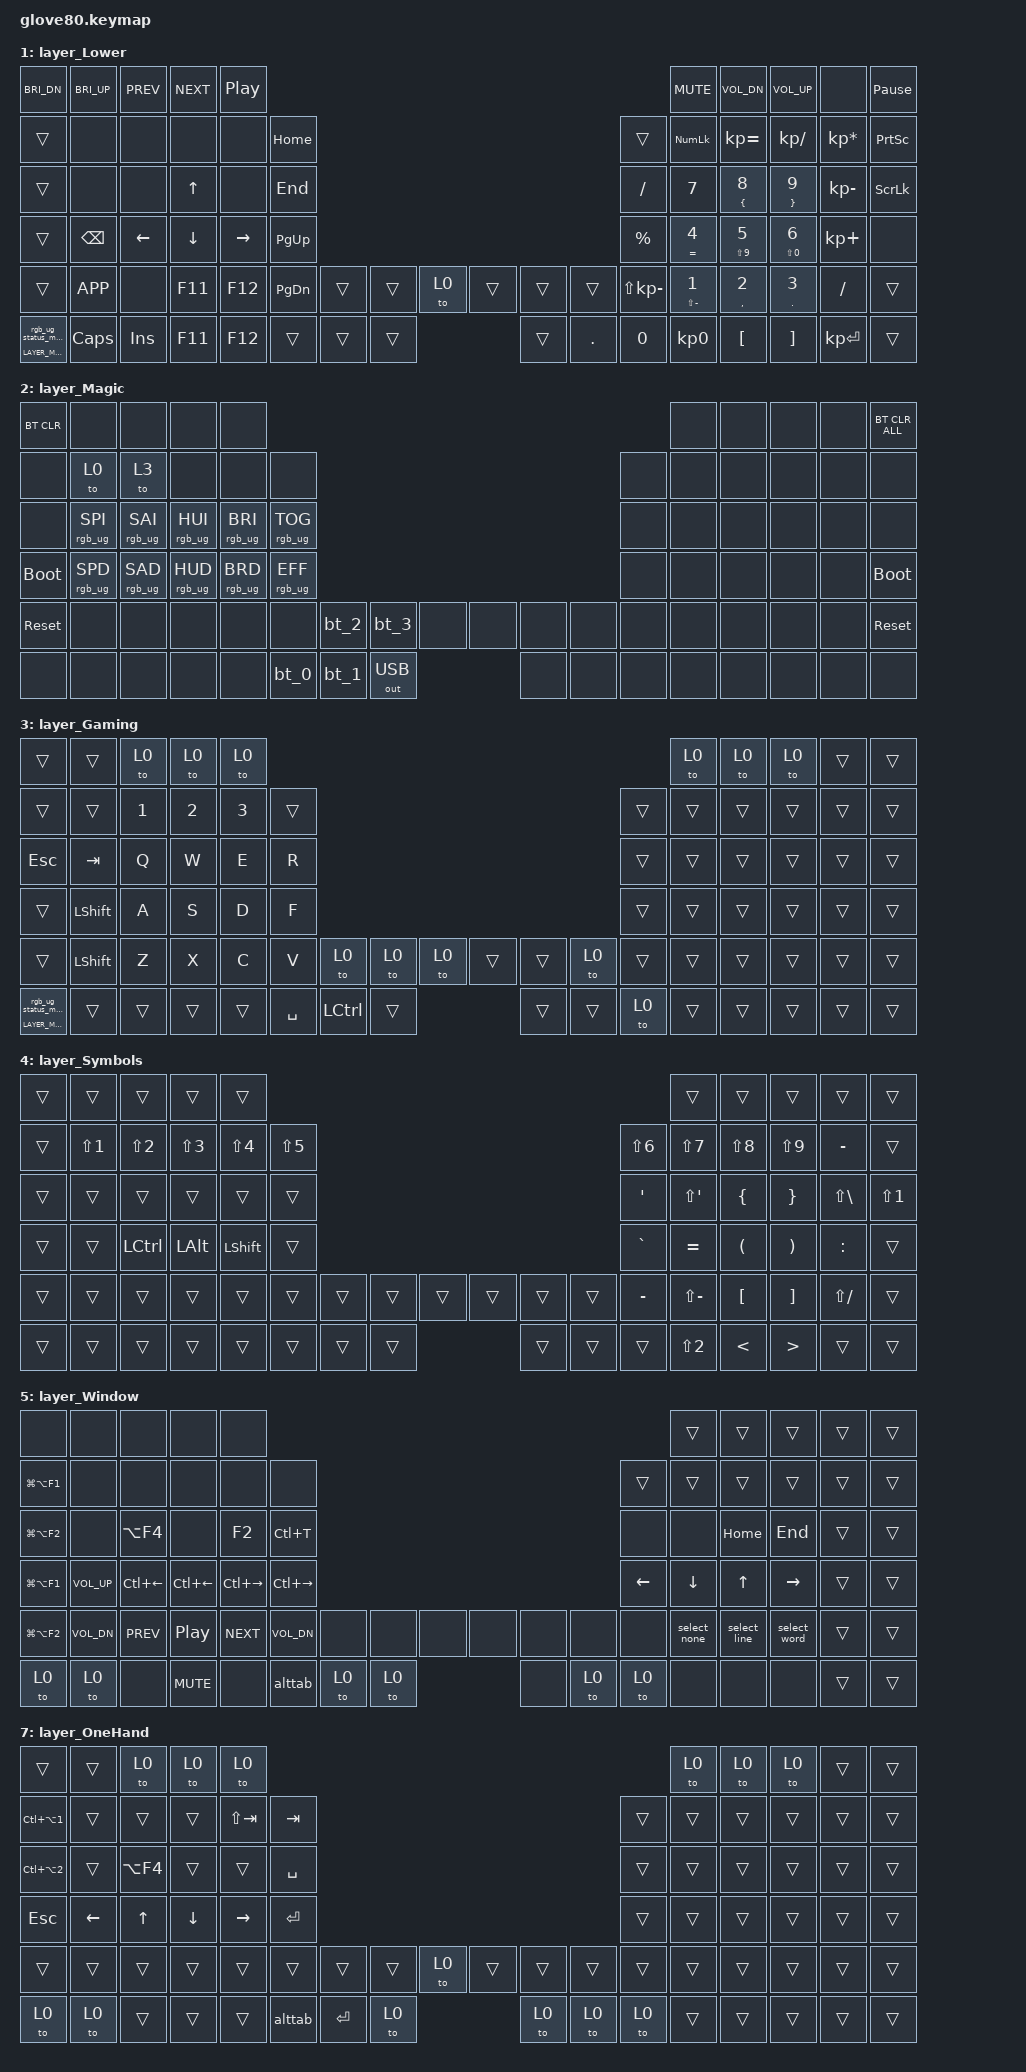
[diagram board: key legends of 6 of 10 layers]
/*
 * Copyright (c) 2020 The ZMK Contributors
 * Copyright (c) 2025 Innaworks Development Limited, trading as MoErgo
 *
 * SPDX-License-Identifier: MIT
 */


/* THIS FILE WAS GENERATED BY GLOVE80 LAYOUT EDITOR
 *
 * This file was generated automatically. You may or may not want to
 * edit it directly.
 */

#include <behaviors.dtsi>
/* Include all behavior includes needed */
#include <dt-bindings/zmk/outputs.h>
#include <dt-bindings/zmk/keys.h>
#include <dt-bindings/zmk/bt.h>
#include <dt-bindings/zmk/rgb.h>

/* On demand includes */


/* Helper Macros, based on https://github.com/urob/zmk-helpers/ */

#pragma once

#define ZMK_HELPER_STRINGIFY(x) #x

// Preprocessor mechanism to overload macros, cf. https://stackoverflow.com/a/27051616/6114651
#define VARGS_(_10, _9, _8, _7, _6, _5, _4, _3, _2, _1, N, ...) N
#define VARGS(...) VARGS_(__VA_ARGS__, 10, 9, 8, 7, 6, 5, 4, 3, 2, 1, 0)
#define CONCAT_(a, b) a##b
#define CONCAT(a, b) CONCAT_(a, b)

#define ZMK_BEHAVIOR_CORE_tap_dance  \
    compatible = "zmk,behavior-tap-dance"; \
    #binding-cells = <0>

#define ZMK_BEHAVIOR(name, type, ...) \
    name: name { \
        ZMK_BEHAVIOR_CORE_ ## type; \
        __VA_ARGS__ \
    };

#define ZMK_TAP_DANCE(name, ...) \
    ZMK_BEHAVIOR(name, tap_dance, __VA_ARGS__)

#define ZMK_TD_LAYER(name, layer) \
    ZMK_TAP_DANCE(name, \
        tapping-term-ms = <200>; \
        bindings = <&mo layer>, <&to layer>; \
)

/* Automatically generated layer name #define */
#define LAYER_Base 0
#define LAYER_Lower 1
#define LAYER_Magic 2
#define LAYER_Gaming 3
#define LAYER_Symbols 4
#define LAYER_Window 5
#define LAYER_Nav 6
#define LAYER_OneHand 7
#define LAYER_Base_mac 8
#define LAYER_Nav_mac 9

/* To deal with the situation where there is no Lower layer, to keep &lower happy */
#ifndef LAYER_Lower
#define LAYER_Lower 0
#endif

/* Custom Device-tree */


/* Input Listeners */


/* System behavior and Macros */
/ {
    behaviors {
        ZMK_TD_LAYER(lower, LAYER_Lower)
    };
};

/ {
    macros {
        rgb_ug_status_macro: rgb_ug_status_macro {
            label = "RGB_UG_STATUS";
            compatible = "zmk,behavior-macro";
            #binding-cells = <0>;
            bindings
                = <&rgb_ug RGB_STATUS>;
        };
    };
};


/ {
#ifdef BT_DISC_CMD
    behaviors {
        bt_0: bt_0 {
            compatible = "zmk,behavior-tap-dance";
            label = "BT_0";
            #binding-cells = <0>;
            tapping-term-ms = <200>;
            bindings = <&bt_select_0>, <&bt BT_DISC 0>;
        };
        bt_1: bt_1 {
            compatible = "zmk,behavior-tap-dance";
            label = "BT_1";
            #binding-cells = <0>;
            tapping-term-ms = <200>;
            bindings = <&bt_select_1>, <&bt BT_DISC 1>;
        };
        bt_2: bt_2 {
            compatible = "zmk,behavior-tap-dance";
            label = "BT_2";
            #binding-cells = <0>;
            tapping-term-ms = <200>;
            bindings = <&bt_select_2>, <&bt BT_DISC 2>;
        };
        bt_3: bt_3 {
            compatible = "zmk,behavior-tap-dance";
            label = "BT_3";
            #binding-cells = <0>;
            tapping-term-ms = <200>;
            bindings = <&bt_select_3>, <&bt BT_DISC 3>;
        };
    };
    macros {
        bt_select_0: bt_select_0 {
            label = "BT_SELECT_0";
            compatible = "zmk,behavior-macro";
            #binding-cells = <0>;
            bindings
                = <&out OUT_BLE>,
                  <&bt BT_SEL 0>;
        };
        bt_select_1: bt_select_1 {
            label = "BT_SELECT_1";
            compatible = "zmk,behavior-macro";
            #binding-cells = <0>;
            bindings
                = <&out OUT_BLE>,
                  <&bt BT_SEL 1>;
        };
        bt_select_2: bt_select_2 {
            label = "BT_SELECT_2";
            compatible = "zmk,behavior-macro";
            #binding-cells = <0>;
            bindings
                = <&out OUT_BLE>,
                  <&bt BT_SEL 2>;
        };
        bt_select_3: bt_select_3 {
            label = "BT_SELECT_3";
            compatible = "zmk,behavior-macro";
            #binding-cells = <0>;
            bindings
                = <&out OUT_BLE>,
                  <&bt BT_SEL 3>;
        };
    };
#else
    macros {
        bt_0: bt_0 {
            label = "BT_0";
            compatible = "zmk,behavior-macro";
            #binding-cells = <0>;
            bindings
                = <&out OUT_BLE>,
                  <&bt BT_SEL 0>;
        };
        bt_1: bt_1 {
            label = "BT_1";
            compatible = "zmk,behavior-macro";
            #binding-cells = <0>;
            bindings
                = <&out OUT_BLE>,
                  <&bt BT_SEL 1>;
        };
        bt_2: bt_2 {
            label = "BT_2";
            compatible = "zmk,behavior-macro";
            #binding-cells = <0>;
            bindings
                = <&out OUT_BLE>,
                  <&bt BT_SEL 2>;
        };
        bt_3: bt_3 {
            label = "BT_3";
            compatible = "zmk,behavior-macro";
            #binding-cells = <0>;
            bindings
                = <&out OUT_BLE>,
                  <&bt BT_SEL 3>;
        };
    };
#endif
};

/ {
    behaviors {
        magic: magic {
            compatible = "zmk,behavior-hold-tap";
            label = "MAGIC_HOLD_TAP";
            #binding-cells = <2>;
            flavor = "tap-preferred";
            tapping-term-ms = <200>;
            bindings = <&mo>, <&rgb_ug_status_macro>;
        };
    };
};

/* #define for key positions */
#define POS_LH_T1 52
#define POS_LH_T2 53
#define POS_LH_T3 54
#define POS_LH_T4 69
#define POS_LH_T5 70
#define POS_LH_T6 71
#define POS_LH_C1R2 15
#define POS_LH_C1R3 27
#define POS_LH_C1R4 39
#define POS_LH_C1R5 51
#define POS_LH_C2R1 4
#define POS_LH_C2R2 14
#define POS_LH_C2R3 26
#define POS_LH_C2R4 38
#define POS_LH_C2R5 50
#define POS_LH_C2R6 68
#define POS_LH_C3R1 3
#define POS_LH_C3R2 13
#define POS_LH_C3R3 25
#define POS_LH_C3R4 37
#define POS_LH_C3R5 49
#define POS_LH_C3R6 67
#define POS_LH_C4R1 2
#define POS_LH_C4R2 12
#define POS_LH_C4R3 24
#define POS_LH_C4R4 36
#define POS_LH_C4R5 48
#define POS_LH_C4R6 66
#define POS_LH_C5R1 1
#define POS_LH_C5R2 11
#define POS_LH_C5R3 23
#define POS_LH_C5R4 35
#define POS_LH_C5R5 47
#define POS_LH_C5R6 65
#define POS_LH_C6R1 0
#define POS_LH_C6R2 10
#define POS_LH_C6R3 22
#define POS_LH_C6R4 34
#define POS_LH_C6R5 46
#define POS_LH_C6R6 64
#define POS_RH_T1 57
#define POS_RH_T2 56
#define POS_RH_T3 55
#define POS_RH_T4 74
#define POS_RH_T5 73
#define POS_RH_T6 72
#define POS_RH_C1R2 16
#define POS_RH_C1R3 28
#define POS_RH_C1R4 40
#define POS_RH_C1R5 58
#define POS_RH_C2R1 5
#define POS_RH_C2R2 17
#define POS_RH_C2R3 29
#define POS_RH_C2R4 41
#define POS_RH_C2R5 59
#define POS_RH_C2R6 75
#define POS_RH_C3R1 6
#define POS_RH_C3R2 18
#define POS_RH_C3R3 30
#define POS_RH_C3R4 42
#define POS_RH_C3R5 60
#define POS_RH_C3R6 76
#define POS_RH_C4R1 7
#define POS_RH_C4R2 19
#define POS_RH_C4R3 31
#define POS_RH_C4R4 43
#define POS_RH_C4R5 61
#define POS_RH_C4R6 77
#define POS_RH_C5R1 8
#define POS_RH_C5R2 20
#define POS_RH_C5R3 32
#define POS_RH_C5R4 44
#define POS_RH_C5R5 62
#define POS_RH_C5R6 78
#define POS_RH_C6R1 9
#define POS_RH_C6R2 21
#define POS_RH_C6R3 33
#define POS_RH_C6R4 45
#define POS_RH_C6R5 63
#define POS_RH_C6R6 79

/* Custom Defined Behaviors */
/ {
// Based on Sunaku's Keymap v29 
// - https://github.com/sunaku/glove80-keymaps

behaviors {

    //////////////////////////////////////////////////////////////////////////
    //
    // Miryoku layers and home row mods (ported from my QMK endgame)
    // - https://sunaku.github.io/home-row-mods.html#porting-to-zmk
    // - https://github.com/urob/zmk-config#timeless-homerow-mods
    //
    //////////////////////////////////////////////////////////////////////////

    //
    // HOMEY_HOLDING_TYPE defines the flavor of ZMK hold-tap behavior to use
    // for the pinky, ring, and middle fingers (which are assigned to Super,
    // Alt, and Ctrl respectively in the Miryoku system) on home row keys.
    //
    #ifndef HOMEY_HOLDING_TYPE
    #define HOMEY_HOLDING_TYPE "tap-preferred"
    #endif

    //
    // HOMEY_HOLDING_TIME defines how long you need to hold (milliseconds)
    // home row mod keys in order to send their modifiers to the computer
    // (i.e. "register" them) for mod-click mouse usage (e.g. Ctrl-Click).
    //
    #ifndef HOMEY_HOLDING_TIME
    #define HOMEY_HOLDING_TIME 200 // TAPPING_TERM + ALLOW_CROSSOVER_AFTER
    #endif

    //
    // HOMEY_STREAK_DECAY defines how long you need to wait (milliseconds)
    // after typing before you can use home row mods again.  It prevents
    // unintended activation of home row mods when you're actively typing.
    //
    #ifndef HOMEY_STREAK_DECAY
    #define HOMEY_STREAK_DECAY 170 // global-quick-tap-ms
    #endif

    //
    // HOMEY_REPEAT_DECAY defines how much time you have left (milliseconds)
    // after tapping a key to hold it again in order to make it auto-repeat.
    //
    #ifndef HOMEY_REPEAT_DECAY
    #define HOMEY_REPEAT_DECAY 300 // "tap then hold" for key auto-repeat
    #endif

    //
    // SHIFT_HOLDING_TYPE defines the flavor of ZMK hold-tap behavior to use
    // for index fingers (which Miryoku assigns to Shift) on home row keys.
    //
    // NOTE: The "tap-preferred" flavor of ZMK hold-tap for index finger keys
    // allows faster activation of the Shift modifier (without having to wait
    // for the modified key to be released as the "balanced" flavor requires).
    // Typing streaks and the `hold-trigger-on-release` setting are disabled
    // for the index fingers so as not to hinder their speed and dexterity.
    //
    #ifndef SHIFT_HOLDING_TYPE
    #define SHIFT_HOLDING_TYPE "tap-preferred"
    #endif

    //
    // SHIFT_HOLDING_TIME defines how long you need to hold (milliseconds)
    // index finger keys in order to send their modifiers to the computer
    // (i.e. "register" them) for mod-click mouse usage (e.g. Shift-Click).
    //
    // CAUTION: You'll need to perform inward rolls from pinky->ring->middle
    // fingers toward the index fingers when activating multiple modifiers
    // because `hold-trigger-on-release` is disabled for the index fingers.
    // Otherwise, you may be surprised that the index fingers' modifier is
    // sent immediately without the rest of your multi-mod chord when you
    // perform outward rolls from your index fingers toward your pinkies.
    //
    #ifndef SHIFT_HOLDING_TIME
    #define SHIFT_HOLDING_TIME 170
    #endif

    //
    // SHIFT_STREAK_DECAY defines how long you need to wait (milliseconds)
    // after typing before you can use home row mods again.  It prevents
    // unintended activation of home row mods when you're actively typing.
    //
    #ifndef SHIFT_STREAK_DECAY
    #define SHIFT_STREAK_DECAY 50 // global-quick-tap-ms
    #endif

    //
    // SHIFT_REPEAT_DECAY defines how much time you have left (milliseconds)
    // after tapping a key to hold it again in order to make it auto-repeat.
    //
    #ifndef SHIFT_REPEAT_DECAY
    #define SHIFT_REPEAT_DECAY 300 // "tap then hold" for key auto-repeat
    #endif

    //
    // THUMB_HOLDING_TYPE defines the flavor of ZMK hold-tap behavior to use
    // for the thumbs (which are assigned to 6 layers in the Miryoku system).
    //
    // NOTE: The "balanced" flavor of ZMK hold-tap provides instant modifier
    // activation for the symbol layer (if the tapped symbol key is released
    // while the thumb layer key is still held down) for quicker programming.
    //
    #ifndef THUMB_HOLDING_TYPE
    #define THUMB_HOLDING_TYPE "balanced"
    #endif

    //
    // THUMB_HOLDING_TIME defines how long you need to hold (milliseconds)
    // a thumb key to activate a layer.  Shorter holds are treated as taps.
    //
    #ifndef THUMB_HOLDING_TIME
    #define THUMB_HOLDING_TIME 230
    #endif

    //
    // THUMB_REPEAT_DECAY defines how much time you have left (milliseconds)
    // after tapping a key to hold it again in order to make it auto-repeat.
    //
    #ifndef THUMB_REPEAT_DECAY
    #define THUMB_REPEAT_DECAY 300 // "tap then hold" for key auto-repeat
    #endif

    //
    // LSPACE_HOLDING_TIME defines how long you need to hold (milliseconds)
    // the LSPACE thumb key to activate.  Shorter holds are treated as taps.
    //
    #ifndef LSPACE_HOLDING_TIME
    #define LSPACE_HOLDING_TIME 270
    #endif

    //
    // LSPACE_REPEAT_DECAY defines how much time you have left (milliseconds)
    // after tapping a key to hold it again in order to make it auto-repeat.
    //
    #ifndef LSPACE_REPEAT_DECAY
    #define LSPACE_REPEAT_DECAY 200 // "tap then hold" for key auto-repeat
    #endif

    //
    // LSPACE_STREAK_DECAY defines how long you need to wait (milliseconds)
    // after typing before you can use home row mods again.  It prevents
    // unintended activation of home row mods when you're actively typing.
    //
    #ifndef LSPACE_STREAK_DECAY
    #define LSPACE_STREAK_DECAY 80 // global-quick-tap-ms
    #endif

    //
    // RSPACE_HOLDING_TIME defines how long you need to hold (milliseconds)
    // the RSPACE thumb key to activate.  Shorter holds are treated as taps.
    //
    #ifndef RSPACE_HOLDING_TIME
    #define RSPACE_HOLDING_TIME 250
    #endif

    //
    // RSPACE_REPEAT_DECAY defines how much time you have left (milliseconds)
    // after tapping a key to hold it again in order to make it auto-repeat.
    //
    #ifndef RSPACE_REPEAT_DECAY
    #define RSPACE_REPEAT_DECAY 200 // "tap then hold" for key auto-repeat
    #endif

    //
    // RSPACE_STREAK_DECAY defines how long you need to wait (milliseconds)
    // after typing before you can use home row mods again.  It prevents
    // unintended activation of home row mods when you're actively typing.
    //
    #ifndef RSPACE_STREAK_DECAY
    #define RSPACE_STREAK_DECAY 250 // global-quick-tap-ms
    #endif

    //
    // Glove80 key positions index for positional hold-tap
    // - https://discord.com/channels/877392805654306816/937645688244826154/1066713913351221248
    // - https://media.discordapp.net/attachments/937645688244826154/1066713913133121556/image.png
    //
    // |------------------------|------------------------|
    // | LEFT_HAND_KEYS         |        RIGHT_HAND_KEYS |
    // |                        |                        |
    // |  0  1  2  3  4         |          5  6  7  8  9 |
    // | 10 11 12 13 14 15      |      16 17 18 19 20 21 |
    // | 22 23 24 25 26 27      |      28 29 30 31 32 33 |
    // | 34 35 36 37 38 39      |      40 41 42 43 44 45 |
    // | 46 47 48 49 50 51      |      58 59 60 61 62 63 |
    // | 64 65 66 67 68         |         75 76 77 78 79 |
    // |                69 52   |   57 74                |
    // |                 70 53  |  56 73                 |
    // |                  71 54 | 55 72                  |
    // |------------------------|------------------------|
    //
    #define LEFT_HAND_KEYS      \
          0  1  2  3  4         \
         10 11 12 13 14 15      \
         22 23 24 25 26 27      \
         34 35 36 37 38 39      \
         46 47 48 49 50 51      \
         64 65 66 67 68
    #define RIGHT_HAND_KEYS     \
                                           5  6  7  8  9 \
                                       16 17 18 19 20 21 \
                                       28 29 30 31 32 33 \
                                       40 41 42 43 44 45 \
                                       58 59 60 61 62 63 \
                                          75 76 77 78 79
    #define THUMB_KEYS          \
                        69 52       57 74                \
                         70 53     56 73                 \
                          71 54   55 72

    // vtr custom
    thumb_to: thumb_to_layer {
        compatible = "zmk,behavior-hold-tap";
        label = "MIRYOKU_THUMB_LAYER";
        flavor = THUMB_HOLDING_TYPE;
        tapping-term-ms = <THUMB_HOLDING_TIME>;
        quick-tap-ms = <THUMB_REPEAT_DECAY>; // enable repeat
        //global-quick-tap; // no typing streak
        //retro-tap; // don't allow slow (hold-like) taps
        #binding-cells = <2>;
        bindings = <&to>, <&kp>;
    };

    // Home row mod-tap keys for all except index fingers
    //
    homey_left: miryoku_home_row_mods_left_hand {
        compatible = "zmk,behavior-hold-tap";
        label = "HOME_ROW_MODS_LEFT_HAND";
        flavor = HOMEY_HOLDING_TYPE;
        hold-trigger-key-positions = <RIGHT_HAND_KEYS THUMB_KEYS>;
        hold-trigger-on-release; // wait for other home row mods
        tapping-term-ms = <HOMEY_HOLDING_TIME>;
        quick-tap-ms = <HOMEY_REPEAT_DECAY>;
        require-prior-idle-ms = <HOMEY_STREAK_DECAY>;
        #binding-cells = <2>;
        bindings = <&kp>, <&kp>;
    };
    homey_right: miryoku_home_row_mods_right_hand {
        compatible = "zmk,behavior-hold-tap";
        label = "HOME_ROW_MODS_RIGHT_HAND";
        flavor = HOMEY_HOLDING_TYPE;
        hold-trigger-key-positions = <LEFT_HAND_KEYS THUMB_KEYS>;
        hold-trigger-on-release; // wait for other home row mods
        tapping-term-ms = <HOMEY_HOLDING_TIME>;
        quick-tap-ms = <HOMEY_REPEAT_DECAY>;
        require-prior-idle-ms = <HOMEY_STREAK_DECAY>;
        #binding-cells = <2>;
        bindings = <&kp>, <&kp>;
    };

    //
    // Special home row mod-tap keys for the index fingers
    //
    shift_left: miryoku_home_row_mods_left_shift_shift {
        compatible = "zmk,behavior-hold-tap";
        label = "HOME_ROW_MODS_LEFT_SHIFT_SHIFT";
        flavor = SHIFT_HOLDING_TYPE;
        hold-trigger-key-positions = <RIGHT_HAND_KEYS THUMB_KEYS>;
        //hold-trigger-on-release; // don't wait for other mods
        tapping-term-ms = <SHIFT_HOLDING_TIME>;
        quick-tap-ms = <SHIFT_REPEAT_DECAY>;
        require-prior-idle-ms = <SHIFT_STREAK_DECAY>;
        #binding-cells = <2>;
        bindings = <&kp>, <&kp>;
    };
    shift_right: miryoku_home_row_mods_right_shift_shift {
        compatible = "zmk,behavior-hold-tap";
        label = "HOME_ROW_MODS_RIGHT_SHIFT_SHIFT";
        flavor = SHIFT_HOLDING_TYPE;
        hold-trigger-key-positions = <LEFT_HAND_KEYS THUMB_KEYS>;
        //hold-trigger-on-release; // don't wait for other mods
        tapping-term-ms = <SHIFT_HOLDING_TIME>;
        quick-tap-ms = <SHIFT_REPEAT_DECAY>;
        require-prior-idle-ms = <SHIFT_STREAK_DECAY>;
        #binding-cells = <2>;
        bindings = <&kp>, <&kp>;
    };

    //
    // Thumb cluster hold-tap keys for Miryoku layers
    //
    thumb: thumb_layer_access {
        compatible = "zmk,behavior-hold-tap";
        label = "THUMB_LAYER_ACCESS";
        flavor = THUMB_HOLDING_TYPE;
        tapping-term-ms = <THUMB_HOLDING_TIME>;
        quick-tap-ms = <THUMB_REPEAT_DECAY>; // enable repeat
        #binding-cells = <2>;
        bindings = <&mo>, <&kp>;
    };
    lspace: miryoku_thumb_layer_lspacebar {
        compatible = "zmk,behavior-hold-tap";
        label = "MIRYOKU_THUMB_LAYER_LSPACEBAR";
        flavor = THUMB_HOLDING_TYPE;
        tapping-term-ms = <LSPACE_HOLDING_TIME>;
        quick-tap-ms = <LSPACE_REPEAT_DECAY>; // enable repeat
        require-prior-idle-ms = <LSPACE_STREAK_DECAY>;
        retro-tap; // allow slow (hold-like) taps
        #binding-cells = <2>;
        bindings = <&mo>, <&kp>;
    };
    rspace: miryoku_thumb_layer_rspacebar {
        compatible = "zmk,behavior-hold-tap";
        label = "MIRYOKU_THUMB_LAYER_RSPACEBAR";
        flavor = THUMB_HOLDING_TYPE;
        tapping-term-ms = <RSPACE_HOLDING_TIME>;
        quick-tap-ms = <RSPACE_REPEAT_DECAY>; // enable repeat
        require-prior-idle-ms = <RSPACE_STREAK_DECAY>;
        retro-tap; // allow slow (hold-like) taps
        #binding-cells = <2>;
        bindings = <&mo>, <&kp>;
    };

    //////////////////////////////////////////////////////////////////////////
    //
    // Custom shifted pairs
    //
    //////////////////////////////////////////////////////////////////////////

    //
    // Shift + CapsWord = CapsLock
    //
    cappy: capsword_and_capslock {
        compatible = "zmk,behavior-mod-morph";
        label = "CAPSWORD_AND_CAPSLOCK";
        #binding-cells = <0>;
        bindings = <&caps_word>, <&kp CAPSLOCK>;
        mods = <(MOD_LSFT|MOD_RSFT)>;
    };

    //////////////////////////////////////////////////////////////////////////
    //
    // ZMK global overrides
    //
    //////////////////////////////////////////////////////////////////////////

    //
    // CapsWord - ported from Pascal Getreuer's extension for QMK
    // - https://zmk.dev/docs/behaviors/caps-word
    // - https://getreuer.info/posts/keyboards/caps-word/index.html
    //
    behavior_caps_word {
        continue-list = <
            UNDERSCORE MINUS
            BACKSPACE DELETE
            N1 N2 N3 N4 N5 N6 N7 N8 N9 N0
        >;
    };

};

    // |------------------------|------------------------|
    // | LEFT_HAND_KEYS         |        RIGHT_HAND_KEYS |
    // |                        |                        |
    // |  0  1  2  3  4         |          5  6  7  8  9 |
    // | 10 11 12 13 14 15      |      16 17 18 19 20 21 |
    // | 22 23 24 25 26 27      |      28 29 30 31 32 33 |
    // | 34 35 36 37 38 39      |      40 41 42 43 44 45 |
    // | 46 47 48 49 50 51      |      58 59 60 61 62 63 |
    // | 64 65 66 67 68         |         75 76 77 78 79 |
    // |                69 52   |   57 74                |
    // |                 70 53  |  56 73                 |
    // |                  71 54 | 55 72                  |
    // |------------------------|------------------------|
    //
combos {
    compatible = "zmk,combos";
    combo_special_e {
            timeout-ms = <100>;
            key-positions = <45 25>;
            bindings = <&kp RA(E)>;
    };
              //ê
    combo_special_e2 {
            timeout-ms = <150>;
            key-positions = <45 44 25>;
            bindings = <&circun_e>;
    };
              //~a
    combo_special_a2 {
            timeout-ms = <100>;
            key-positions = <45 35>;
            bindings = <&tild_a>;
    };
              //á
    combo_special_a {
            timeout-ms = <100>;
            key-positions = <45 44 35>;
            bindings = <&kp RA(A)>;
    };
              //ó
    combo_special_o {
            timeout-ms = <100>;
            key-positions = <45 31>;
            bindings = <&kp RA(O)>;
    };
              //ç
    combo_special_c {
            timeout-ms = <100>;
            key-positions = <45 49>;
            bindings = <&kp RA(C)>;
    };
};

macros {
    // vtr custom
    // special letters
              // ~a
    ZMK_MACRO(tild_a,
        wait-ms = <10>;
        tap-ms = <40>;
        bindings = <&kp LS(GRAVE) &kp A>;
    )
              // ê
    ZMK_MACRO(circun_e,
        wait-ms = <10>;
        tap-ms = <40>;
        bindings = <&kp LS(NUMBER_6) &kp E>;
    )
    // window movement
    ZMK_MACRO(alttab,
        bindings =  <&macro_press &kp LALT> // leave GUI down to keep menu up
                , <&macro_tap &kp TAB> // combines with shift fine
                , <&macro_tap &sk LALT> // this will release GUI after a timeout
                , <&macro_release &kp LALT> // now release the previous hold
                        ;
        )
    ZMK_MACRO(winleft,
        bindings =  <&macro_press &kp LGUI> // leave GUI down to keep menu up
                , <&macro_tap &kp LEFT> // combines with shift fine
                , <&macro_tap &sk LGUI> // this will release GUI after a timeout
                , <&macro_release &kp LGUI> // now release the previous hold
                        ;
        )
    ZMK_MACRO(winright,
        bindings =  <&macro_press &kp LGUI> // leave GUI down to keep menu up
                , <&macro_tap &kp RIGHT> // combines with shift fine
                , <&macro_tap &sk LGUI> // this will release GUI after a timeout
                , <&macro_release &kp LGUI> // now release the previous hold
                        ;
        )
    ZMK_MACRO(winup,
        bindings =  <&macro_press &kp LGUI> // leave GUI down to keep menu up
                , <&macro_tap &kp UP> // combines with shift fine
                , <&macro_tap &sk LGUI> // this will release GUI after a timeout
                , <&macro_release &kp LGUI> // now release the previous hold
                        ;
        )
    ZMK_MACRO(windown,
        bindings =  <&macro_press &kp LGUI> // leave GUI down to keep menu up
                , <&macro_tap &kp DOWN> // combines with shift fine
                , <&macro_tap &sk LGUI> // this will release GUI after a timeout
                , <&macro_release &kp LGUI> // now release the previous hold
                        ;
        )
    ZMK_MACRO(winbar,
        bindings =  <&macro_press &kp LGUI> // leave GUI down to keep menu up
                , <&macro_tap &kp SPACE> // combines with shift fine
                , <&macro_release &kp LGUI> // now release the previous hold
                        ;
    )
    //////////////////////////////////////////////////////////////////////////
    //
    // Approximation of Pascal Getreuer's Select Word macro from QMK
    // - https://getreuer.info/posts/keyboards/select-word/index.html
    //
    //////////////////////////////////////////////////////////////////////////
    //
    // SELECT_WORD_DELAY defines how long the macro waits (milliseconds)
    // after moving the cursor before it selects a word.  A larger delay
    // may allow the macro to move to the next word upon each invocation.
    //
    #ifndef SELECT_WORD_DELAY
    #define SELECT_WORD_DELAY 1
    #endif

    ZMK_MACRO(select_none,
        wait-ms = <SELECT_WORD_DELAY>;
        tap-ms = <SELECT_WORD_DELAY>;
        bindings = <&kp DOWN &kp UP &kp RIGHT &kp LEFT>;
    )

    //
    // select a word (jumps to next word upon each successive invocation)
    //
    select_word: select_word {
        compatible = "zmk,behavior-mod-morph";
        label = "SELECT_WORD";
        #binding-cells = <0>;
        bindings = <&select_word_right>, <&select_word_left>;
        mods = <(MOD_LSFT|MOD_RSFT)>;
    };
    ZMK_MACRO(select_word_right,
        wait-ms = <SELECT_WORD_DELAY>;
        tap-ms = <SELECT_WORD_DELAY>;
        bindings = <&kp LC(RIGHT) &kp LC(LEFT) &kp LC(LS(RIGHT))>;
    )
    ZMK_MACRO(select_word_left,
        wait-ms = <SELECT_WORD_DELAY>;
        tap-ms = <SELECT_WORD_DELAY>;
        bindings = <&kp LC(LEFT) &kp LC(RIGHT) &kp LC(LS(LEFT))>;
    )

    //
    // extend current selection by one word
    //
    extend_word: extend_word {
        compatible = "zmk,behavior-mod-morph";
        label = "EXTEND_WORD";
        #binding-cells = <0>;
        bindings = <&extend_word_right>, <&extend_word_left>;
        mods = <(MOD_LSFT|MOD_RSFT)>;
    };
    ZMK_MACRO(extend_word_right,
        wait-ms = <SELECT_WORD_DELAY>;
        tap-ms = <SELECT_WORD_DELAY>;
        bindings = <&kp LC(LS(RIGHT))>;
    )
    ZMK_MACRO(extend_word_left,
        wait-ms = <SELECT_WORD_DELAY>;
        tap-ms = <SELECT_WORD_DELAY>;
        bindings = <&kp LC(LS(LEFT))>;
    )

    //
    // select current line
    //
    select_line: select_line {
        compatible = "zmk,behavior-mod-morph";
        label = "SELECT_LINE";
        #binding-cells = <0>;
        bindings = <&select_line_right>, <&select_line_left>;
        mods = <(MOD_LSFT|MOD_RSFT)>;
    };
    ZMK_MACRO(select_line_right,
        wait-ms = <SELECT_WORD_DELAY>;
        tap-ms = <SELECT_WORD_DELAY>;
        bindings = <&kp HOME &kp LS(END)>;
    )
    ZMK_MACRO(select_line_left,
        wait-ms = <SELECT_WORD_DELAY>;
        tap-ms = <SELECT_WORD_DELAY>;
        bindings = <&kp END &kp LS(HOME)>;
    )

    //
    // extend current selection by one line
    //
    extend_line: extend_line {
        compatible = "zmk,behavior-mod-morph";
        label = "EXTEND_LINE";
        #binding-cells = <0>;
        bindings = <&extend_line_right>, <&extend_line_left>;
        mods = <(MOD_LSFT|MOD_RSFT)>;
    };
    ZMK_MACRO(extend_line_right,
        wait-ms = <SELECT_WORD_DELAY>;
        tap-ms = <SELECT_WORD_DELAY>;
        bindings = <&kp LS(DOWN) &kp LS(END)>;
    )
    ZMK_MACRO(extend_line_left,
        wait-ms = <SELECT_WORD_DELAY>;
        tap-ms = <SELECT_WORD_DELAY>;
        bindings = <&kp LS(UP) &kp LS(HOME)>;
    )
};

};

/* Automatically generated macro definitions */
/ {
    macros {

        // Opens the Mac finder
        macsearch: macsearch {
            label = "&MACSEARCH";
            compatible = "zmk,behavior-macro";
            #binding-cells = <0>;
            bindings = <&macro_press>
                , <&kp LGUI>
                , <&macro_tap>
                , <&kp SPACE>
                , <&macro_release>
                , <&kp LGUI>;
        };

        // Opens the Mac finder
        macmissioncontrol: macmissioncontrol {
            label = "&MACMISSIONCONTROL";
            compatible = "zmk,behavior-macro";
            #binding-cells = <0>;
            bindings = <&macro_press>
                , <&kp LCTRL>
                , <&macro_tap>
                , <&kp UP>
                , <&macro_release>
                , <&kp LCTRL>;
        };
    };
};

/* Automatically generated behavior definitions */
/ {
    behaviors {


        // Opens finder on mac. Opens Search on Windows
        search: search {
            compatible = "zmk,behavior-hold-tap";
            #binding-cells = <2>;
            tapping-term-ms = <200>;
            bindings = <&kp>, <&kp>;
            hold-while-undecided;
            hold-while-undecided-linger;
            hold-trigger-on-release;
        };
    };
};

/* Automatically generated combos definitions */
/ {
      combos {
          compatible = "zmk,combos";
                  // Switching to mac mode
        combo_macmode {
            timeout-ms = <100>;
            key-positions = <57 52>;
            bindings = <&tog 8>;
            layers = <0>;
            require-prior-idle-ms = <20>;
        };

        // Switching to mac mode
        combo_winmode {
            timeout-ms = <100>;
            key-positions = <57 52>;
            bindings = <&tog 0>;
            layers = <8>;
            require-prior-idle-ms = <20>;
        };
      };
    };

/* Automatically generated keymap */
/ {
    keymap {
        compatible = "zmk,keymap";


        layer_Base {
            bindings = <
               &kp F1              &kp F2                   &to 3                   &to 7                  &kp F5                                                                                                                                        &kp F6               &kp F7                &kp F8                  &kp F9    &kp F10
            &kp EQUAL              &kp N1                  &kp N2                  &kp N3                  &kp N4  &kp N5                                                                                                          &kp N6                &kp N7               &kp N8                &kp N9                   &none  &kp MINUS
              &kp TAB               &kp Q                   &kp W                   &kp E        &homey_left F5 R   &kp T                                                                                                           &kp Y                 &kp U                &kp I                 &kp O      &homey_right F11 P   &kp BSLH
              &kp ESC  &homey_left LGUI A     &homey_left LCTRL S      &homey_left LALT D     &shift_left LSHFT F   &kp G                                                                                                           &kp H  &shift_right RSHFT J  &homey_right LALT K  &homey_right RCTRL L  &homey_right RGUI SEMI    &kp SQT
            &kp GRAVE               &kp Z  &homey_left LC ( X ) X  &homey_left LC ( C ) C  &homey_left LC ( V ) V   &kp B        &lspace 6 TAB       &caps_word  &alttab                &kp RGUI        &kp LGUI            &sl 6   &kp N                 &kp M            &kp COMMA               &kp DOT       &mt LS(FSLH) FSLH      &none
 &magic LAYER_Magic 0               &none                   &none                   &none                   &none          &lspace 4 BACKSPACE  &thumb 1 DELETE  &alttab  &thumb &winbar &alttab  &thumb 5 ENTER  &rspace 5 SPACE                         &none                &none                 &none                   &none      &none
            >;
        };

        layer_Lower {
            bindings = <
         &kp C_BRI_DN  &kp C_BRI_UP      &kp C_PREV      &kp C_NEXT         &kp C_PP                                                                                      &kp C_MUTE   &kp C_VOL_DN   &kp C_VOL_UP            &none  &kp PAUSE_BREAK
               &trans         &none           &none           &none            &none   &kp HOME                                                             &trans        &kp KP_NUM   &kp KP_EQUAL   &kp KP_SLASH  &kp KP_MULTIPLY  &kp PRINTSCREEN
               &trans         &none           &none    &kp UP_ARROW            &none    &kp END                                                           &kp FSLH            &kp N7    &mt LBRC N8    &mt RBRC N9     &kp KP_MINUS   &kp SCROLLLOCK
               &trans      &kp BSPC  &kp LEFT_ARROW  &kp DOWN_ARROW  &kp RIGHT_ARROW  &kp PG_UP                                                        &kp PERCENT      &mt EQUAL N4  &mt LS(N9) N5  &mt LS(N0) N6      &kp KP_PLUS            &none
               &trans     &kp K_APP           &none         &kp F11          &kp F12  &kp PG_DN  &trans  &trans   &to 0  &trans   &trans  &trans  &kp LS(KP_MINUS)  &mt LS(MINUS) N1   &mt COMMA N2     &mt DOT N3         &kp FSLH           &trans
 &magic LAYER_Magic 0      &kp CAPS         &kp INS         &kp F11          &kp F12             &trans  &trans  &trans  &trans  &kp DOT  &kp N0                           &kp KP_N0       &kp LBKT       &kp RBKT     &kp KP_ENTER           &trans
            >;
        };

        layer_Magic {
            bindings = <
  &bt BT_CLR            &none            &none            &none            &none                                                                                  &none   &none   &none   &none  &bt BT_CLR_ALL
       &none            &to 0            &to 3            &none            &none            &none                                                         &none   &none   &none   &none   &none           &none
       &none  &rgb_ug RGB_SPI  &rgb_ug RGB_SAI  &rgb_ug RGB_HUI  &rgb_ug RGB_BRI  &rgb_ug RGB_TOG                                                         &none   &none   &none   &none   &none           &none
 &bootloader  &rgb_ug RGB_SPD  &rgb_ug RGB_SAD  &rgb_ug RGB_HUD  &rgb_ug RGB_BRD  &rgb_ug RGB_EFF                                                         &none   &none   &none   &none   &none     &bootloader
  &sys_reset            &none            &none            &none            &none            &none   &bt_2   &bt_3         &none   &none   &none   &none   &none   &none   &none   &none   &none      &sys_reset
       &none            &none            &none            &none            &none                    &bt_0   &bt_1  &out OUT_USB   &none   &none   &none           &none   &none   &none   &none           &none
            >;
        };

        layer_Gaming {
            bindings = <
               &trans     &trans   &to 0   &to 0   &to 0                                                                         &to 0   &to 0   &to 0  &trans  &trans
               &trans     &trans  &kp N1  &kp N2  &kp N3  &trans                                                        &trans  &trans  &trans  &trans  &trans  &trans
              &kp ESC    &kp TAB   &kp Q   &kp W   &kp E   &kp R                                                        &trans  &trans  &trans  &trans  &trans  &trans
               &trans  &kp LSHFT   &kp A   &kp S   &kp D   &kp F                                                        &trans  &trans  &trans  &trans  &trans  &trans
               &trans  &kp LSHFT   &kp Z   &kp X   &kp C   &kp V      &to 0      &to 0   &to 0  &trans  &trans   &to 0  &trans  &trans  &trans  &trans  &trans  &trans
 &magic LAYER_Magic 0     &trans  &trans  &trans  &trans          &kp SPACE  &kp LCTRL  &trans  &trans  &trans   &to 0          &trans  &trans  &trans  &trans  &trans
            >;
        };

        layer_Symbols {
            bindings = <
 &trans      &trans      &trans      &trans      &trans                                                                                 &trans      &trans      &trans        &trans      &trans
 &trans  &kp LS(N1)  &kp LS(N2)  &kp LS(N3)  &kp LS(N4)  &kp LS(N5)                                                  &kp LS(N6)     &kp LS(N7)  &kp LS(N8)  &kp LS(N9)     &kp MINUS      &trans
 &trans      &trans      &trans      &trans      &trans      &trans                                                     &kp SQT    &kp LS(SQT)    &kp LBRC    &kp RBRC  &kp LS(BSLH)  &kp LS(N1)
 &trans      &trans   &kp LCTRL    &kp LALT   &kp LSHFT      &trans                                                   &kp GRAVE      &kp EQUAL    &kp LPAR    &kp RPAR     &kp COLON      &trans
 &trans      &trans      &trans      &trans      &trans      &trans  &trans  &trans  &trans  &trans  &trans  &trans   &kp MINUS  &kp LS(MINUS)    &kp LBKT    &kp RBKT  &kp LS(FSLH)      &trans
 &trans      &trans      &trans      &trans      &trans              &trans  &trans  &trans  &trans  &trans  &trans                 &kp LS(N2)      &kp LT      &kp GT        &trans      &trans
            >;
        };

        layer_Window {
            bindings = <
          &none         &none         &none         &none          &none                                                                                  &trans        &trans        &trans  &trans  &trans
 &kp LG(LA(F1))         &none         &none         &none          &none          &none                                                     &trans        &trans        &trans        &trans  &trans  &trans
 &kp LG(LA(F2))         &none    &kp LA(F4)         &none         &kp F2      &kp LC(T)                                                      &none         &none      &kp HOME       &kp END  &trans  &trans
 &kp LG(LA(F1))  &kp C_VOL_UP  &kp LC(LEFT)  &kp LC(LEFT)  &kp LC(RIGHT)  &kp LC(RIGHT)                                                   &kp LEFT      &kp DOWN        &kp UP     &kp RIGHT  &trans  &trans
 &kp LG(LA(F2))  &kp C_VOL_DN    &kp C_PREV      &kp C_PP     &kp C_NEXT   &kp C_VOL_DN    &none   &none   &none   &none   &none   &none     &none  &select_none  &select_line  &select_word  &trans  &trans
          &to 0         &to 0         &none    &kp C_MUTE          &none                 &alttab   &to 0   &to 0   &none   &to 0   &to 0                   &none         &none         &none  &trans  &trans
            >;
        };

        layer_Nav {
            bindings = <
          &none           &none              &none              &none              &none                                                                                                                              &trans              &trans              &trans              &trans  &trans
 &kp LG(LA(F1))           &none              &none              &none              &none              &none                                                                                        &none               &none               &none               &none               &none  &trans
 &kp LG(LA(F2))  &kp LC(LA(N1))     &kp LC(LA(N2))     &kp LC(LA(N3))     &kp LC(LA(N4))     &kp LC(LA(N5))                                                                           &kp LC(LA(LS(N1)))  &kp LC(LA(LS(N2)))  &kp LC(LA(LS(N3)))  &kp LA(LC(LS(N4)))  &kp LC(LA(LS(N5)))  &trans
 &kp LG(LA(F1))    &kp C_VOL_DN  &kp LC(LA(LS(H)))  &kp LC(LA(LS(J)))  &kp LC(LA(LS(K)))  &kp LC(LA(LS(L)))                                                                                &kp LC(LA(H))       &kp LC(LA(J))       &kp LC(LA(K))       &kp LC(LA(L))       &kp LC(LA(X))  &trans
 &kp LG(LA(F2))    &kp C_VOL_UP          &kp LA(D)          &kp LA(S)          &kp LA(R)      &kp LA(LS(P))  &kp LA(D)      &none   &none   &none  &macmissioncontrol  &kp LC(LA(D))   &kp LC(LA(LS(P)))       &kp LC(LA(F))       &kp LC(LA(V))       &kp LC(LA(M))       &kp LC(LA(Y))  &trans
          &to 0           &to 0              &none              &none              &none                       &alttab  &kp LA(S)   &to 0   &none           &kp LA(D)          &to 0                                   &none               &none               &none               &none  &trans
            >;
        };

        layer_OneHand {
            bindings = <
         &trans    &trans       &to 0     &to 0        &to 0                                                                        &to 0   &to 0   &to 0  &trans  &trans
 &kp LC(LA(N1))    &trans      &trans    &trans  &kp LS(TAB)    &kp TAB                                                    &trans  &trans  &trans  &trans  &trans  &trans
 &kp LC(LA(N2))    &trans  &kp LA(F4)    &trans       &trans  &kp SPACE                                                    &trans  &trans  &trans  &trans  &trans  &trans
        &kp ESC  &kp LEFT      &kp UP  &kp DOWN    &kp RIGHT    &kp RET                                                    &trans  &trans  &trans  &trans  &trans  &trans
         &trans    &trans      &trans    &trans       &trans     &trans   &trans   &trans   &to 0  &trans  &trans  &trans  &trans  &trans  &trans  &trans  &trans  &trans
          &to 0     &to 0      &trans    &trans       &trans             &alttab  &kp RET   &to 0   &to 0   &to 0   &to 0          &trans  &trans  &trans  &trans  &trans
            >;
        };

        layer_Base_mac {
            bindings = <
               &kp F1              &kp F2                   &to 3                   &to 7                  &kp F5                                                                                                                                        &kp F6               &kp F7                &kp F8                  &kp F9    &kp F10
            &kp EQUAL              &kp N1                  &kp N2                  &kp N3                  &kp N4  &kp N5                                                                                                          &kp N6                &kp N7               &kp N8                &kp N9                   &none  &kp MINUS
              &kp TAB               &kp Q                   &kp W                   &kp E        &homey_left F5 R   &kp T                                                                                                           &kp Y                 &kp U                &kp I                 &kp O      &homey_right F11 P   &kp BSLH
              &kp ESC  &homey_left LGUI A     &homey_left LCTRL S      &homey_left LALT D     &shift_left LSHFT F   &kp G                                                                                                           &kp H  &shift_right RSHFT J  &homey_right LALT K  &homey_right RCTRL L  &homey_right RGUI SEMI    &kp SQT
            &kp GRAVE               &kp Z  &homey_left LC ( X ) X  &homey_left LC ( C ) C  &homey_left LC ( V ) V   &kp B        &lspace 9 TAB       &caps_word   &tog 0                &kp RGUI      &macsearch            &sl 9   &kp N                 &kp M            &kp COMMA               &kp DOT       &mt LS(FSLH) FSLH      &none
 &magic LAYER_Magic 0               &none                   &none                   &none                  &tog 0          &lspace 4 BACKSPACE  &thumb 1 DELETE  &alttab  &thumb &winbar &alttab  &thumb 5 ENTER  &rspace 5 SPACE                        &tog 0                &none                 &none                   &none      &none
            >;
        };

        layer_Nav_mac {
            bindings = <
          &none           &none              &none              &none              &none                                                                                                                              &trans              &trans              &trans              &trans  &trans
 &kp LG(LA(F1))           &none              &none              &none              &none              &none                                                                                        &none               &none               &none               &none               &none  &trans
 &kp LG(LA(F2))  &kp LC(LA(N1))     &kp LC(LA(N2))     &kp LC(LA(N3))     &kp LC(LA(N4))     &kp LC(LA(N5))                                                                           &kp LC(LA(LS(N1)))  &kp LC(LA(LS(N2)))  &kp LC(LA(LS(N3)))  &kp LA(LC(LS(N4)))  &kp LC(LA(LS(N5)))  &trans
 &kp LG(LA(F1))    &kp C_VOL_DN  &kp LC(LA(LS(H)))  &kp LC(LA(LS(J)))  &kp LC(LA(LS(K)))  &kp LC(LA(LS(L)))                                                                                 &kp LC(LEFT)       &kp LC(LA(J))       &kp LC(LA(K))       &kp LC(RIGHT)       &kp LC(LA(X))  &trans
 &kp LG(LA(F2))    &kp C_VOL_UP          &kp LA(D)          &kp LA(S)          &kp LA(R)      &kp LA(LS(P))  &kp LA(D)      &none   &none   &none  &macmissioncontrol  &kp LC(LA(D))   &kp LC(LA(LS(P)))  &macmissioncontrol       &kp LC(LA(V))       &kp LC(LA(M))       &kp LC(LA(Y))  &trans
          &to 0           &to 0              &none              &none              &none                       &alttab  &kp LA(S)   &to 0   &none           &kp LA(D)          &to 0                                   &none               &none               &none               &none  &trans
            >;
        };

    };
};
